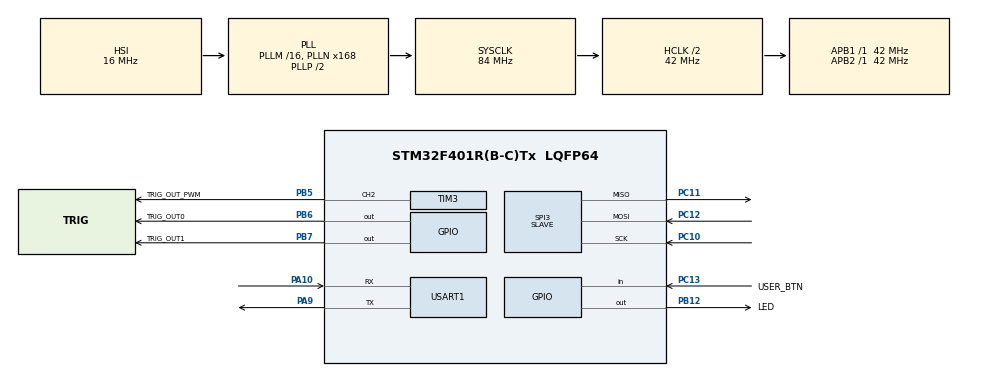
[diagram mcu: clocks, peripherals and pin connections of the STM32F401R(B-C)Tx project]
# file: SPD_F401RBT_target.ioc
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Dma.Request0=USART1_RX
Dma.Request1=USART1_TX
Dma.USART1_RX.0.Direction=DMA_PERIPH_TO_MEMORY
Dma.USART1_RX.0.FIFOMode=DMA_FIFOMODE_ENABLE
Dma.USART1_RX.0.FIFOThreshold=DMA_FIFO_THRESHOLD_FULL
Dma.USART1_RX.0.Instance=DMA2_Stream2
Dma.USART1_RX.0.MemBurst=DMA_MBURST_SINGLE
Dma.USART1_RX.0.MemDataAlignment=DMA_MDATAALIGN_BYTE
Dma.USART1_RX.0.MemInc=DMA_MINC_ENABLE
Dma.USART1_RX.0.Mode=DMA_NORMAL
Dma.USART1_RX.0.PeriphBurst=DMA_PBURST_SINGLE
Dma.USART1_RX.0.PeriphDataAlignment=DMA_PDATAALIGN_BYTE
Dma.USART1_RX.0.PeriphInc=DMA_PINC_DISABLE
Dma.USART1_RX.0.Priority=DMA_PRIORITY_LOW
Dma.USART1_TX.1.Direction=DMA_MEMORY_TO_PERIPH
Dma.USART1_TX.1.FIFOMode=DMA_FIFOMODE_DISABLE
Dma.USART1_TX.1.Instance=DMA2_Stream7
Dma.USART1_TX.1.MemDataAlignment=DMA_MDATAALIGN_BYTE
Dma.USART1_TX.1.MemInc=DMA_MINC_ENABLE
Dma.USART1_TX.1.Mode=DMA_NORMAL
Dma.USART1_TX.1.PeriphDataAlignment=DMA_PDATAALIGN_BYTE
Dma.USART1_TX.1.PeriphInc=DMA_PINC_DISABLE
Dma.USART1_TX.1.Priority=DMA_PRIORITY_LOW
Mcu.Family=STM32F4
Mcu.Name=STM32F401R(B-C)Tx
Mcu.Package=LQFP64
NVIC.DMA2_Stream2_IRQn=true\:0\:0\:false\:false\:true\:false\:true\:true
NVIC.DMA2_Stream7_IRQn=true\:0\:0\:false\:false\:true\:false\:true\:true
NVIC.PriorityGroup=NVIC_PRIORITYGROUP_4
NVIC.TIM3_IRQn=true\:0\:0\:false\:false\:true\:true\:true\:true
NVIC.USART1_IRQn=true\:0\:0\:false\:false\:true\:true\:true\:true
PA10.Mode=Asynchronous
PA10.Signal=USART1_RX
PA9.Mode=Asynchronous
PA9.Signal=USART1_TX
PB12.GPIO_Label=LED
PB12.Signal=GPIO_Output
PB5.GPIO_Label=TRIG_OUT_PWM
PB5.Signal=S_TIM3_CH2
PB6.GPIO_Label=TRIG_OUT0
PB6.Signal=GPIO_Output
PB7.GPIO_Label=TRIG_OUT1
PB7.Signal=GPIO_Output
PC10.Mode=Full_Duplex_Slave
PC10.Signal=SPI3_SCK
PC11.Mode=Full_Duplex_Slave
PC11.Signal=SPI3_MISO
PC12.Mode=Full_Duplex_Slave
PC12.Signal=SPI3_MOSI
PC13-ANTI_TAMP.GPIO_Label=USER_BTN
PC13-ANTI_TAMP.Signal=GPIO_Input
ProjectManager.HeapSize=0x200
ProjectManager.StackSize=0x400
ProjectManager.TargetToolchain=STM32CubeIDE
RCC.48MHZClocksFreq_Value=42000000
RCC.AHBCLKDivider=RCC_SYSCLK_DIV2
RCC.AHBFreq_Value=42000000
RCC.APB1Freq_Value=42000000
RCC.APB1TimFreq_Value=42000000
RCC.APB2Freq_Value=42000000
RCC.APB2TimFreq_Value=42000000
RCC.CortexFreq_Value=42000000
RCC.HCLKFreq_Value=42000000
RCC.HSE_VALUE=25000000
RCC.HSI_VALUE=16000000
RCC.LSE_VALUE=32768
RCC.PLLN=168
RCC.SYSCLKFreq_VALUE=84000000
RCC.SYSCLKSource=RCC_SYSCLKSOURCE_PLLCLK
RCC.VCOOutputFreq_Value=168000000
SH.S_TIM3_CH2.0=TIM3_CH2,PWM Generation2 CH2
SPI3.Direction=SPI_DIRECTION_2LINES
SPI3.Mode=SPI_MODE_SLAVE
SPI3.VirtualType=VM_SLAVE
TIM3.AutoReloadPreload=TIM_AUTORELOAD_PRELOAD_ENABLE
TIM3.Channel-PWM\ Generation2\ CH2=TIM_CHANNEL_2
TIM3.OCFastMode_PWM-PWM\ Generation2\ CH2=TIM_OCFAST_ENABLE
TIM3.Period=10
TIM3.Prescaler=15999
TIM3.Pulse-PWM\ Generation2\ CH2=5
USART1.VirtualMode=VM_ASYNC
VP_TIM3_VS_ClockSourceINT.Mode=Internal
board=custom

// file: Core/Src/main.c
/* USER CODE BEGIN Header */
/**
  ******************************************************************************
  * @file           : main.c
  * @brief          : Main program body
  ******************************************************************************
  * @attention
  *
  * Copyright (c) 2023 STMicroelectronics.
  * All rights reserved.
  *
  * This software is licensed under terms that can be found in the LICENSE file
  * in the root directory of this software component.
  * If no LICENSE file comes with this software, it is provided AS-IS.
  *
  ******************************************************************************
  */
/* USER CODE END Header */
#include "main.h"

SPI_HandleTypeDef hspi3;

TIM_HandleTypeDef htim3;

UART_HandleTypeDef huart1;
DMA_HandleTypeDef hdma_usart1_rx;
DMA_HandleTypeDef hdma_usart1_tx;

void SystemClock_Config(void);
static void MX_GPIO_Init(void);
static void MX_DMA_Init(void);
static void MX_TIM3_Init(void);
static void MX_USART1_UART_Init(void);
static void MX_SPI3_Init(void);

int main(void)
{

  /* MCU Configuration--------------------------------------------------------*/

  /* Reset of all peripherals, Initializes the Flash interface and the Systick. */
  HAL_Init();

  /* Configure the system clock */
  SystemClock_Config();

  /* Initialize all configured peripherals */
  MX_GPIO_Init();
  MX_DMA_Init();
  MX_TIM3_Init();
  MX_USART1_UART_Init();
  MX_SPI3_Init();
  /* USER CODE BEGIN 2 */
  Init_Cmd_Handling(&htim3, &huart1, &hdma_usart1_tx, &hspi3); // Just associate the correct pointers to local ones

  Start_Cmd_Reception();
  /* USER CODE END 2 */

  /* Infinite loop */
  while (1)
  {

  }
}

void SystemClock_Config(void)
{
  RCC_OscInitTypeDef RCC_OscInitStruct = {0};
  RCC_ClkInitTypeDef RCC_ClkInitStruct = {0};

  /** Configure the main internal regulator output voltage
  */
  __HAL_RCC_PWR_CLK_ENABLE();
  __HAL_PWR_VOLTAGESCALING_CONFIG(PWR_REGULATOR_VOLTAGE_SCALE2);

  /** Initializes the RCC Oscillators according to the specified parameters
  * in the RCC_OscInitTypeDef structure.
  */
  RCC_OscInitStruct.OscillatorType = RCC_OSCILLATORTYPE_HSI;
  RCC_OscInitStruct.HSIState = RCC_HSI_ON;
  RCC_OscInitStruct.HSICalibrationValue = RCC_HSICALIBRATION_DEFAULT;
  RCC_OscInitStruct.PLL.PLLState = RCC_PLL_ON;
  RCC_OscInitStruct.PLL.PLLSource = RCC_PLLSOURCE_HSI;
  RCC_OscInitStruct.PLL.PLLM = 16;
  RCC_OscInitStruct.PLL.PLLN = 168;
  RCC_OscInitStruct.PLL.PLLP = RCC_PLLP_DIV2;
  RCC_OscInitStruct.PLL.PLLQ = 4;
  if (HAL_RCC_OscConfig(&RCC_OscInitStruct) != HAL_OK)
  {
    Error_Handler();
  }

  /** Initializes the CPU, AHB and APB buses clocks
  */
  RCC_ClkInitStruct.ClockType = RCC_CLOCKTYPE_HCLK|RCC_CLOCKTYPE_SYSCLK
                              |RCC_CLOCKTYPE_PCLK1|RCC_CLOCKTYPE_PCLK2;
  RCC_ClkInitStruct.SYSCLKSource = RCC_SYSCLKSOURCE_PLLCLK;
  RCC_ClkInitStruct.AHBCLKDivider = RCC_SYSCLK_DIV2;
  RCC_ClkInitStruct.APB1CLKDivider = RCC_HCLK_DIV1;
  RCC_ClkInitStruct.APB2CLKDivider = RCC_HCLK_DIV1;

  if (HAL_RCC_ClockConfig(&RCC_ClkInitStruct, FLASH_LATENCY_1) != HAL_OK)
  {
    Error_Handler();
  }
}

static void MX_SPI3_Init(void)
{

  /* SPI3 parameter configuration*/
  hspi3.Instance = SPI3;
  hspi3.Init.Mode = SPI_MODE_SLAVE;
  hspi3.Init.Direction = SPI_DIRECTION_2LINES;
  hspi3.Init.DataSize = SPI_DATASIZE_8BIT;
  hspi3.Init.CLKPolarity = SPI_POLARITY_LOW;
  hspi3.Init.CLKPhase = SPI_PHASE_1EDGE;
  hspi3.Init.NSS = SPI_NSS_SOFT;
  hspi3.Init.FirstBit = SPI_FIRSTBIT_MSB;
  hspi3.Init.TIMode = SPI_TIMODE_DISABLE;
  hspi3.Init.CRCCalculation = SPI_CRCCALCULATION_DISABLE;
  hspi3.Init.CRCPolynomial = 10;
  if (HAL_SPI_Init(&hspi3) != HAL_OK)
  {
    Error_Handler();
  }

}

static void MX_TIM3_Init(void)
{

  TIM_ClockConfigTypeDef sClockSourceConfig = {0};
  TIM_MasterConfigTypeDef sMasterConfig = {0};
  TIM_OC_InitTypeDef sConfigOC = {0};

  htim3.Instance = TIM3;
  htim3.Init.Prescaler = 15999;
  htim3.Init.CounterMode = TIM_COUNTERMODE_UP;
  htim3.Init.Period = 10;
  htim3.Init.ClockDivision = TIM_CLOCKDIVISION_DIV1;
  htim3.Init.AutoReloadPreload = TIM_AUTORELOAD_PRELOAD_ENABLE;
  if (HAL_TIM_Base_Init(&htim3) != HAL_OK)
  {
    Error_Handler();
  }
  sClockSourceConfig.ClockSource = TIM_CLOCKSOURCE_INTERNAL;
  if (HAL_TIM_ConfigClockSource(&htim3, &sClockSourceConfig) != HAL_OK)
  {
    Error_Handler();
  }
  if (HAL_TIM_PWM_Init(&htim3) != HAL_OK)
  {
    Error_Handler();
  }
  sMasterConfig.MasterOutputTrigger = TIM_TRGO_RESET;
  sMasterConfig.MasterSlaveMode = TIM_MASTERSLAVEMODE_DISABLE;
  if (HAL_TIMEx_MasterConfigSynchronization(&htim3, &sMasterConfig) != HAL_OK)
  {
    Error_Handler();
  }
  sConfigOC.OCMode = TIM_OCMODE_PWM1;
  sConfigOC.Pulse = 5;
  sConfigOC.OCPolarity = TIM_OCPOLARITY_HIGH;
  sConfigOC.OCFastMode = TIM_OCFAST_ENABLE;
  if (HAL_TIM_PWM_ConfigChannel(&htim3, &sConfigOC, TIM_CHANNEL_2) != HAL_OK)
  {
    Error_Handler();
  }
  HAL_TIM_MspPostInit(&htim3);

}

static void MX_USART1_UART_Init(void)
{

  huart1.Instance = USART1;
  huart1.Init.BaudRate = 115200;
  huart1.Init.WordLength = UART_WORDLENGTH_8B;
  huart1.Init.StopBits = UART_STOPBITS_1;
  huart1.Init.Parity = UART_PARITY_NONE;
  huart1.Init.Mode = UART_MODE_TX_RX;
  huart1.Init.HwFlowCtl = UART_HWCONTROL_NONE;
  huart1.Init.OverSampling = UART_OVERSAMPLING_16;
  if (HAL_UART_Init(&huart1) != HAL_OK)
  {
    Error_Handler();
  }

}

static void MX_DMA_Init(void)
{

  /* DMA controller clock enable */
  __HAL_RCC_DMA2_CLK_ENABLE();

  /* DMA interrupt init */
  /* DMA2_Stream2_IRQn interrupt configuration */
  HAL_NVIC_SetPriority(DMA2_Stream2_IRQn, 0, 0);
  HAL_NVIC_EnableIRQ(DMA2_Stream2_IRQn);
  /* DMA2_Stream7_IRQn interrupt configuration */
  HAL_NVIC_SetPriority(DMA2_Stream7_IRQn, 0, 0);
  HAL_NVIC_EnableIRQ(DMA2_Stream7_IRQn);

}

static void MX_GPIO_Init(void)
{
  GPIO_InitTypeDef GPIO_InitStruct = {0};

  /* GPIO Ports Clock Enable */
  __HAL_RCC_GPIOC_CLK_ENABLE();
  __HAL_RCC_GPIOB_CLK_ENABLE();
  __HAL_RCC_GPIOA_CLK_ENABLE();

  /*Configure GPIO pin Output Level */
  HAL_GPIO_WritePin(GPIOB, LED_Pin|TRIG_OUT0_Pin|TRIG_OUT1_Pin, GPIO_PIN_RESET);

  /*Configure GPIO pin : USER_BTN_Pin */
  GPIO_InitStruct.Pin = USER_BTN_Pin;
  GPIO_InitStruct.Mode = GPIO_MODE_INPUT;
  GPIO_InitStruct.Pull = GPIO_NOPULL;
  HAL_GPIO_Init(USER_BTN_GPIO_Port, &GPIO_InitStruct);

  /*Configure GPIO pins : LED_Pin TRIG_OUT0_Pin TRIG_OUT1_Pin */
  GPIO_InitStruct.Pin = LED_Pin|TRIG_OUT0_Pin|TRIG_OUT1_Pin;
  GPIO_InitStruct.Mode = GPIO_MODE_OUTPUT_PP;
  GPIO_InitStruct.Pull = GPIO_NOPULL;
  GPIO_InitStruct.Speed = GPIO_SPEED_FREQ_LOW;
  HAL_GPIO_Init(GPIOB, &GPIO_InitStruct);

}

void Error_Handler(void)
{
  __disable_irq();
  while (1)
  {
  }
}
